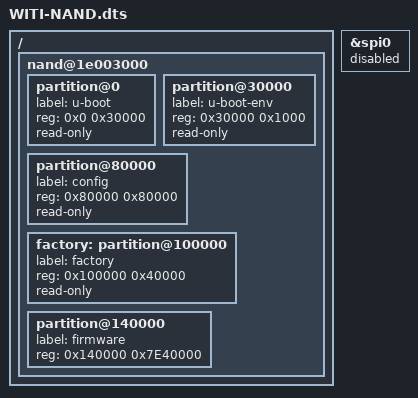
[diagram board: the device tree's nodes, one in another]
/dts-v1/;

#include "WITI.dtsi"

/ {
	nand@1e003000 {
		status = "okay";

		partition@0 {
			label = "u-boot";
			reg = <0x0 0x30000>;
			read-only;
		};

		partition@30000 {
			label = "u-boot-env";
			reg = <0x30000 0x1000>;
			read-only;
		};

		partition@80000 {
			label = "config";
			reg = <0x80000 0x80000>;
			read-only;
		};

		factory: partition@100000 {
			label = "factory";
			reg = <0x100000 0x40000>;
			read-only;
		};

		partition@140000 {
			label = "firmware";
			reg = <0x140000 0x7E40000>;
		};
	};
};

&spi0 {
	status = "disabled";
};
